# ATmega1284RFR2 register map
Vendor: Atmel; File version: 1.0
CPU: other r0p0, little endian, no MPU, no FPU, 4 interrupt priority bits
Registers are 8-bit, read-write, reset 0x0 unless marked. A register's access mark holds for its fields unless they carry their own. Offsets are from the block's base; [hi:lo] are bit positions.

## TC4 — Timer/Counter, 16-bit
Base 0x00000039
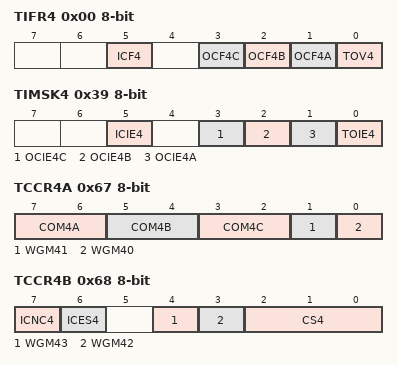
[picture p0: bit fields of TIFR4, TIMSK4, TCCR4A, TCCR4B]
0x00 TIFR4 — Timer/Counter4 Interrupt Flag Register
  [5] ICF4 — Timer/Counter4 Input Capture Flag
  [3] OCF4C — Timer/Counter4 Output Compare C Match Flag
  [2] OCF4B — Timer/Counter4 Output Compare B Match Flag
  [1] OCF4A — Timer/Counter4 Output Compare A Match Flag
  [0] TOV4 — Timer/Counter4 Overflow Flag
0x39 TIMSK4 — Timer/Counter4 Interrupt Mask Register
  [5] ICIE4 — Timer/Counter4 Input Capture Interrupt Enable
  [3] OCIE4C — Timer/Counter4 Output Compare C Match Interrupt Enable
  [2] OCIE4B — Timer/Counter4 Output Compare B Match Interrupt Enable
  [1] OCIE4A — Timer/Counter4 Output Compare A Match Interrupt Enable
  [0] TOIE4 — Timer/Counter4 Overflow Interrupt Enable
0x67 TCCR4A — Timer/Counter4 Control Register A
  [7:6] COM4A — Compare Output Mode for Channel A
    0=Normal operation
  [5:4] COM4B — Compare Output Mode for Channel B
    0=Normal operation
  [3:2] COM4C — Compare Output Mode for Channel C
    0=Normal operation
  [1] WGM41 — Waveform Generation Mode
  [0] WGM40 — Waveform Generation Mode
0x68 TCCR4B — Timer/Counter4 Control Register B
  [7] ICNC4 — Input Capture 4 Noise Canceller
  [6] ICES4 — Input Capture 4 Edge Select
  [4] WGM43 — Waveform Generation Mode
  [3] WGM42 — Waveform Generation Mode
  [2:0] CS4 — Clock Select
    0=No clock source (Timer/Counter stopped); 1=clk_IO/1 (no prescaling); 2=clk_IO/8 (from prescaler); 3=clk_IO/64 (from prescaler); 4=clk_IO/256 (from prescaler); 5=clk_IO/1024 (from prescaler)
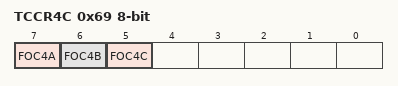
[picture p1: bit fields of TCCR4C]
0x69 TCCR4C — Timer/Counter4 Control Register C
  [7] FOC4A — Force Output Compare for Channel A
  [6] FOC4B — Force Output Compare for Channel B
  [5] FOC4C — Force Output Compare for Channel C
0x6B TCNT4 16-bit (reset mask 0xFF) — Timer/Counter4 Bytes
0x6D ICR4 16-bit (reset mask 0xFF) — Timer/Counter4 Input Capture Register Bytes
0x6F OCR4A 16-bit (reset mask 0xFF) — Timer/Counter4 Output Compare Register A Bytes
0x71 OCR4B 16-bit (reset mask 0xFF) — Timer/Counter4 Output Compare Register B Bytes
0x73 OCR4C 16-bit (reset mask 0xFF) — Timer/Counter4 Output Compare Register C Bytes

## TC5 — Timer/Counter, 16-bit
Base 0x0000003A
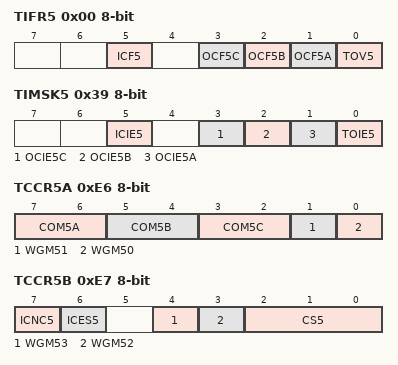
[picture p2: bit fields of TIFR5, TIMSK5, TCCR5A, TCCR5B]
0x00 TIFR5 — Timer/Counter5 Interrupt Flag Register
  [5] ICF5 — Timer/Counter5 Input Capture Flag
  [3] OCF5C — Timer/Counter5 Output Compare C Match Flag
  [2] OCF5B — Timer/Counter5 Output Compare B Match Flag
  [1] OCF5A — Timer/Counter5 Output Compare A Match Flag
  [0] TOV5 — Timer/Counter5 Overflow Flag
0x39 TIMSK5 — Timer/Counter5 Interrupt Mask Register
  [5] ICIE5 — Timer/Counter5 Input Capture Interrupt Enable
  [3] OCIE5C — Timer/Counter5 Output Compare C Match Interrupt Enable
  [2] OCIE5B — Timer/Counter5 Output Compare B Match Interrupt Enable
  [1] OCIE5A — Timer/Counter5 Output Compare A Match Interrupt Enable
  [0] TOIE5 — Timer/Counter5 Overflow Interrupt Enable
0xE6 TCCR5A — Timer/Counter5 Control Register A
  [7:6] COM5A — Compare Output Mode for Channel A
    0=Normal operation
  [5:4] COM5B — Compare Output Mode for Channel B
    0=Normal operation
  [3:2] COM5C — Compare Output Mode for Channel C
    0=Normal operation
  [1] WGM51 — Waveform Generation Mode
  [0] WGM50 — Waveform Generation Mode
0xE7 TCCR5B — Timer/Counter5 Control Register B
  [7] ICNC5 — Input Capture 5 Noise Canceller
  [6] ICES5 — Input Capture 5 Edge Select
  [4] WGM53 — Waveform Generation Mode
  [3] WGM52 — Waveform Generation Mode
  [2:0] CS5 — Clock Select
    0=No clock source (Timer/Counter stopped); 1=clk_IO/1 (no prescaling); 2=clk_IO/8 (from prescaler); 3=clk_IO/64 (from prescaler); 4=clk_IO/256 (from prescaler); 5=clk_IO/1024 (from prescaler)
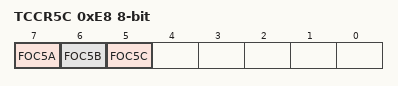
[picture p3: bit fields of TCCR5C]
0xE8 TCCR5C — Timer/Counter5 Control Register C
  [7] FOC5A — Force Output Compare for Channel A
  [6] FOC5B — Force Output Compare for Channel B
  [5] FOC5C — Force Output Compare for Channel C
0xEA TCNT5 16-bit (reset mask 0xFF) — Timer/Counter5 Bytes
0xEC ICR5 16-bit (reset mask 0xFF) — Timer/Counter5 Input Capture Register Bytes
0xEE OCR5A 16-bit (reset mask 0xFF) — Timer/Counter5 Output Compare Register A Bytes
0xF0 OCR5B 16-bit (reset mask 0xFF) — Timer/Counter5 Output Compare Register B Bytes
0xF2 OCR5C 16-bit (reset mask 0xFF) — Timer/Counter5 Output Compare Register C Bytes
